AUTOSAR XML (schema 00048)
standard types defined: boolean, uint16
package /Atomic
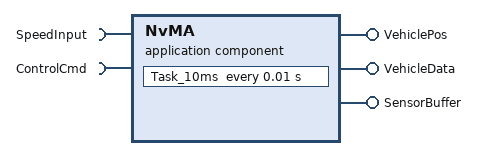
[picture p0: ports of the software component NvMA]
  application sw component type NvMA
    require port SpeedInput: nonqueued-receiver-com-spec{data-element=SpeedInput, init-value=0}, required-interface=SpeedInput
    require port ControlCmd: nonqueued-receiver-com-spec{data-element=ControlCmd, init-value=0}, required-interface=ControlCmd
    provide port VehiclePos: nonqueued-sender-com-spec{data-element=VehiclePos, init-value={short-label=Position_Init, fields=[0, 0]}}, provided-interface=VehiclePos
    provide port VehicleData: nonqueued-sender-com-spec{data-element=VehicleData, init-value={short-label=VehicleInfo_Init, fields=[{short-label=e_Init, fields=[0, 0]}, 0, 0]}}, provided-interface=VehicleData
    provide port SensorBuffer: nonqueued-sender-com-spec{data-element=SensorBuffer, init-value=9 x 0}, provided-interface=SensorBuffer
    behavior default
      timing event Task_10ms: start-on-event=Task_10ms, period=0.01
      runnable Task_10ms
        data-read-access:
          access SpeedInput: accessed-variable=SpeedInput.SpeedInput
        data-read-access:
          access ControlCmd: accessed-variable=ControlCmd.ControlCmd
        data-write-access:
          access VehiclePos: accessed-variable=VehiclePos.VehiclePos
        data-write-access:
          access VehicleData: accessed-variable=VehicleData.VehicleData
        data-write-access:
          access SensorBuffer: accessed-variable=SensorBuffer.SensorBuffer
package /InterfaceTypes
  5 x sender receiver interface:
    SpeedInput
      data SpeedInput: type=uint16
    ControlCmd
      data ControlCmd: type=boolean
    VehiclePos
      data VehiclePos: type=Position
    VehicleData
      data VehicleData: type=VehicleInfo
    SensorBuffer
      data SensorBuffer: type=uint8_array_9
package /SwBaseTypes
  impl type uint8_array_9: category=ARRAY
    element Element: array-size=9, array-size-semantics=FIXED-SIZE, implementation-data-type=uint8
  impl type Position: category=STRUCTURE
    element q: implementation-data-type=uint16
    element w: implementation-data-type=uint16
  impl type VehicleInfo: category=STRUCTURE
    element e: implementation-data-type=Position
    element r: implementation-data-type=uint32
    element t: implementation-data-type=boolean
